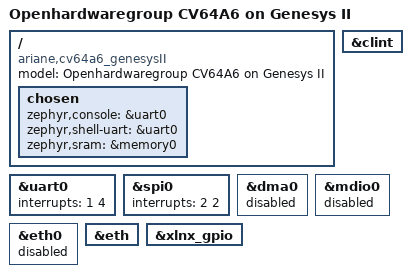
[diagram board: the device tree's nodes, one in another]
/*
 * Copyright (c) 2024 CISPA Helmholtz Center for Information Security gGmbH
 *
 * SPDX-License-Identifier: Apache-2.0
 */
/dts-v1/;

#include <openhwgroup/cv64a6.dtsi>

/ {
	model = "Openhardwaregroup CV64A6 on Genesys II";
	compatible = "ariane,cv64a6_genesysII";

	chosen {
		zephyr,console = &uart0;
		zephyr,shell-uart = &uart0;
		zephyr,sram = &memory0;
	};
};

&uart0 {
	status = "okay";
	// different interrupt than the CISPA version of the SoC
	interrupts = <1 4>;
};

&spi0 {
	status = "okay";
	// different interrupt than the CISPA version of the SoC
	interrupts = <2 2>;
};

&clint{
	status = "okay";
};

&dma0 {
	status = "disabled";
};


&mdio0{
	status = "disabled";
};

&eth0 {
	status = "disabled";
};

&eth {
	status = "okay";
};

&xlnx_gpio {
	status = "okay";
};


